# R7FA2A2AD register map
Vendor: Renesas Electronics Corporation; Series: RA2A2; File version: 1.20.02
CPU: CM23 r1p0, little endian, MPU, no FPU, VTOR, 2 interrupt priority bits, 32 interrupts
Registers are 8-bit, read-write, reset 0x0 unless marked. A register's access mark holds for its fields unless they carry their own. Offsets are from the block's base; [hi:lo] are bit positions; {n}, {i} and the like mark numbered series; 'fields as' and 'values as' point back to an identical list.

## BUS — BUS Control
Base 0x40003000
0x1008 BUSMCNTSYS 16-bit — Master Bus Control Register SYS
  [15] IERES — Ignore Error Responses
0x100C BUSMCNTDMA 16-bit — Master Bus Control Register DMA
  [15] IERES — Ignore Error Responses
0x1820 BUS3ERRADD 32-bit ro reset not defined — Bus Error Address Register 3
  [31:0] BERAD — Bus Error Address
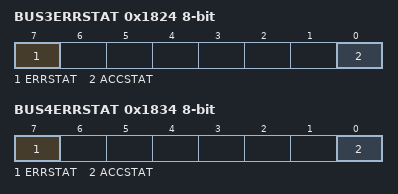
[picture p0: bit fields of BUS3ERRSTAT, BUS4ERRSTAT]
0x1824 BUS3ERRSTAT ro (reset mask 0xFE) — BUS Error Status Register 3
  [7] ERRSTAT — Bus Error Status flag
  [0] ACCSTAT — Error Access Status flag
0x1830 BUS4ERRADD 32-bit ro reset not defined — Bus Error Address Register 4
  [31:0] BERAD — Bus Error Address
0x1834 BUS4ERRSTAT ro (reset mask 0xFE) — BUS Error Status Register 4
  fields as BUS3ERRSTAT

## DTC — Data Transfer Controller
Base 0x40005400
0x00 DTCCR reset 0x8 — DTC Control Register
  [4] RRS — DTC Transfer Information Read Skip Enable
0x04 DTCVBR 32-bit — DTC Vector Base Register
0x0C DTCST — DTC Module Start Register
  [0] DTCST — DTC Module Start
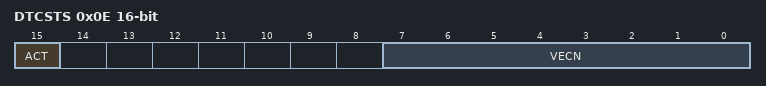
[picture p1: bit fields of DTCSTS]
0x0E DTCSTS 16-bit ro — DTC Status Register
  [15] ACT — DTC Active Flag
  [7:0] VECN — DTC,Activating Vector Number Monitoring

## DBG — Debug Function
Base 0x4001B000
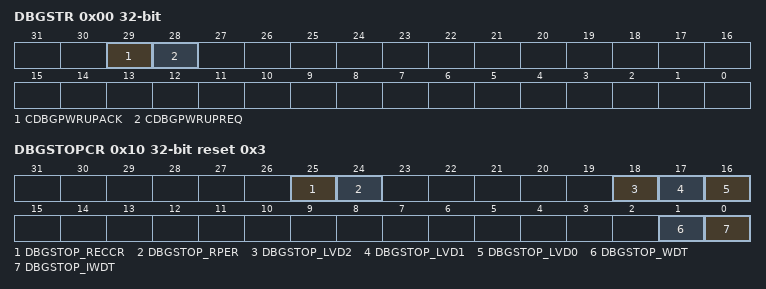
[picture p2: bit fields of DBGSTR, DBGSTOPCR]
0x00 DBGSTR 32-bit ro — Debug Status Register
  [29] CDBGPWRUPACK — Debug power,up acknowledge
  [28] CDBGPWRUPREQ — Debug power,up request
0x10 DBGSTOPCR 32-bit reset 0x3 — Debug Stop Control Register
  [25] DBGSTOP_RECCR — Mask bit for SRAM ECC error reset/interrupt
  [24] DBGSTOP_RPER — Mask bit for SRAM parity error reset/interrupt
  [18] DBGSTOP_LVD2 — Mask bit for LVD2 reset/interrupt
  [17] DBGSTOP_LVD1 — Mask bit for LVD1 reset/interrupt
  [16] DBGSTOP_LVD0 — Mask bit for LVD0 reset
  [1] DBGSTOP_WDT — Mask bit for WDT reset/interrupt in the OCD run mode
  [0] DBGSTOP_IWDT — Mask bit for IWDT reset/interrupt in the OCD run mode

## PORT0 — Port 0 Control Registers
Base 0x40040000
Same registers: PORT3 0x40040060, PORT4 0x40040080, PORT5 0x400400A0, PORT6 0x400400C0
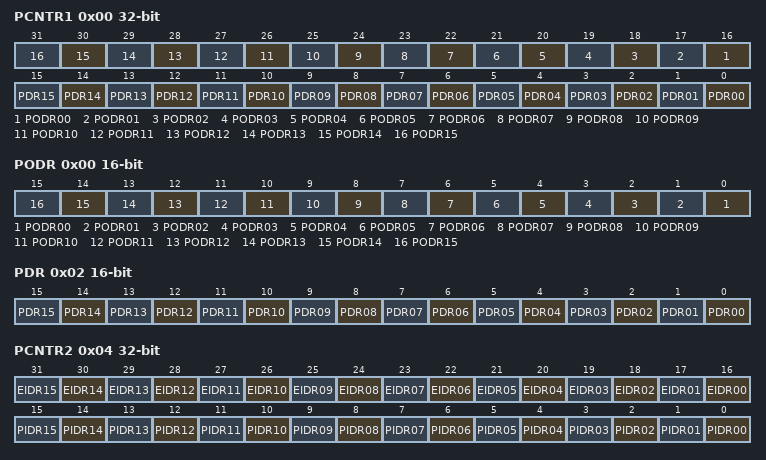
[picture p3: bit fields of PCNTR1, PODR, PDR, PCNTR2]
0x00 PCNTR1 32-bit — Port Control Register 1
  [n+16] PODR{n:02} (n=0..15) — Pmn Output Data
  [n] PDR{n:02} (n=0..15) — Pmn Direction
0x00 PODR 16-bit (alternate view of PCNTR1) — Port Control Register 1
  [n] PODR{n:02} (n=0..15) — Pmn Output Data
0x02 PDR 16-bit (alternate view of PCNTR1) — Port Control Register 1
  [n] PDR{n:02} (n=0..15) — Pmn Direction
0x04 PCNTR2 32-bit ro (reset mask 0xFFFF0000) — Port Control Register 2
  [n+16] EIDR{n:02} (n=0..15) — Port Event Input Data
  [n] PIDR{n:02} (n=0..15) — Pmn State
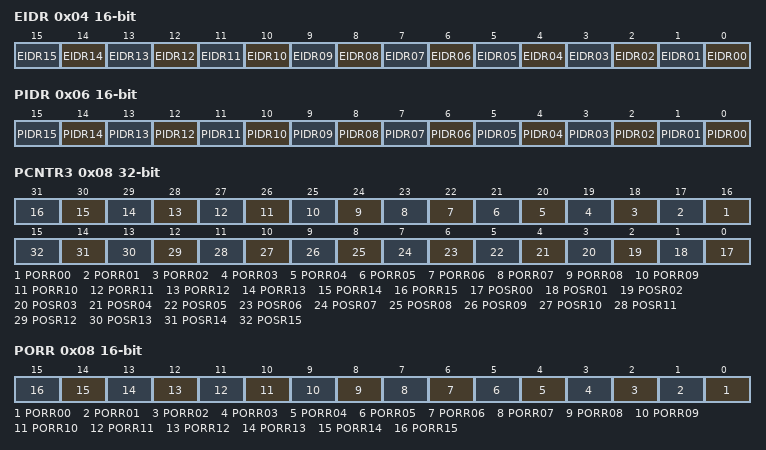
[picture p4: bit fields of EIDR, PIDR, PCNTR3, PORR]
0x04 EIDR 16-bit ro (alternate view of PCNTR2) — Port Control Register 2
  [n] EIDR{n:02} (n=0..15) — Port Event Input Data
0x06 PIDR 16-bit ro reset not defined (alternate view of PCNTR2) — Port Control Register 2
  [n] PIDR{n:02} (n=0..15) — Pmn State
0x08 PCNTR3 32-bit wo — Port Control Register 3
  [n+16] PORR{n:02} (n=0..15) — Pmn Output Reset
  [n] POSR{n:02} (n=0..15) — Pmn Output Set
0x08 PORR 16-bit wo (alternate view of PCNTR3) — Port Control Register 3
  [n] PORR{n:02} (n=0..15) — Pmn Output Reset
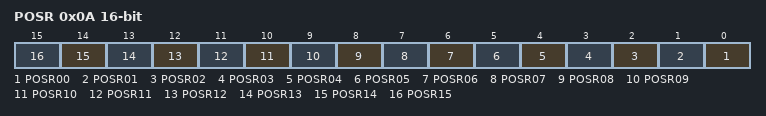
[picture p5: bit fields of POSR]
0x0A POSR 16-bit wo (alternate view of PCNTR3) — Port Control Register 3
  [n] POSR{n:02} (n=0..15) — Pmn Output Set

## PORT1 — Port 1 Control Registers
Base 0x40040020
Same registers: PORT2 0x40040040
Registers as PORT0; these are added or differ:
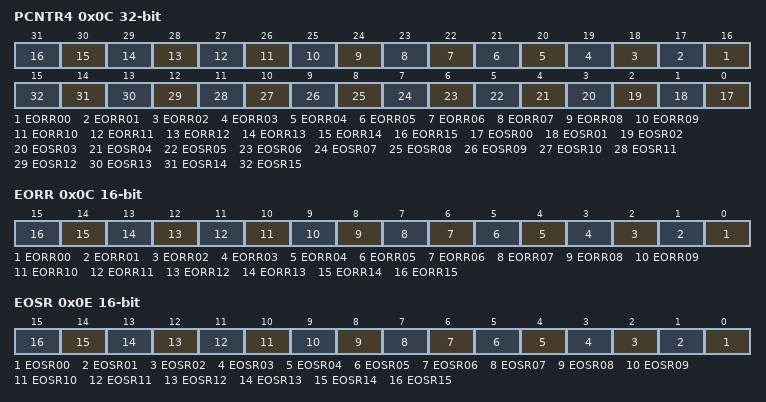
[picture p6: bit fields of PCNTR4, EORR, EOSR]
0x0C PCNTR4 32-bit — Port Control Register 4
  [n+16] EORR{n:02} (n=0..15) — Pmn Event Output Reset
  [n] EOSR{n:02} (n=0..15) — Pmn Event Output Set
0x0C EORR 16-bit (alternate view of PCNTR4) — Port Control Register 4
  [n] EORR{n:02} (n=0..15) — Pmn Event Output Reset
0x0E EOSR 16-bit (alternate view of PCNTR4) — Port Control Register 4
  [n] EOSR{n:02} (n=0..15) — Pmn Event Output Set
